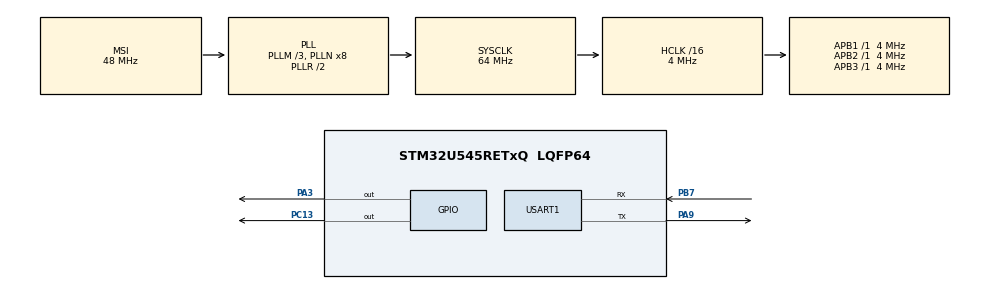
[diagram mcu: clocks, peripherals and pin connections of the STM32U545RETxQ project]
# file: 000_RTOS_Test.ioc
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CORTEX_M33_NS.userName=CORTEX_M33
Mcu.Family=STM32U5
Mcu.Name=STM32U545RETxQ
Mcu.Package=LQFP64
NVIC.PriorityGroup=NVIC_PRIORITYGROUP_4
NVIC.TIM4_IRQn=true\:15\:0\:false\:false\:true\:false\:false\:true\:true
NVIC.TimeBase=TIM4_IRQn
NVIC.TimeBaseIP=TIM4
NVIC.USART1_IRQn=true\:2\:0\:true\:false\:true\:false\:true\:true\:true
PA13\ (JTMS/SWDIO).Mode=Serial_Wire
PA13\ (JTMS/SWDIO).Signal=DEBUG_JTMS-SWDIO
PA14\ (JTCK/SWCLK).Mode=Serial_Wire
PA14\ (JTCK/SWCLK).Signal=DEBUG_JTCK-SWCLK
PA3.Signal=GPIO_Output
PA9.Mode=Asynchronous
PA9.Signal=USART1_TX
PB7.Mode=Asynchronous
PB7.Signal=USART1_RX
PC13.PinState=GPIO_PIN_SET
PC13.Signal=GPIO_Output
PWR.PowerMode=PWR_SMPS_SUPPLY
ProjectManager.HeapSize=0x200
ProjectManager.StackSize=0x400
ProjectManager.TargetToolchain=STM32CubeIDE
RCC.ADCFreq_Value=16000000
RCC.AHBCLKDivider=RCC_SYSCLK_DIV16
RCC.AHBFreq_Value=4000000
RCC.APB1Freq_Value=4000000
RCC.APB1TimFreq_Value=4000000
RCC.APB2Freq_Value=4000000
RCC.APB2TimFreq_Value=4000000
RCC.APB3Freq_Value=4000000
RCC.CortexFreq_Value=4000000
RCC.DACCLockSelectionVirtual=RCC_DAC1CLKSOURCE_LSI
RCC.DACCLockSelectionVirtualString=RCC_DAC1CLKSOURCE_LSI
RCC.EPOD_VALUE=48000000
RCC.HCLKFreq_Value=4000000
RCC.HSE_VALUE=16000000
RCC.HSI48_VALUE=48000000
RCC.HSI_VALUE=16000000
RCC.LSE_VALUE=32768
RCC.LSIDIV_VALUE=32000
RCC.MSIClockRange=RCC_MSIRANGE_0
RCC.MSI_VALUE=48000000
RCC.PLL2FRACN=0
RCC.PLL3FRACN=0
RCC.PLLFRACN=0
RCC.PLLM=3
RCC.PLLN=8
RCC.SYSCLKFreq_VALUE=64000000
RCC.SYSCLKSource=RCC_SYSCLKSOURCE_PLLCLK
RCC.USBFreq_Value=48000000
RCC.VCOOutputFreq_Value=128000000
USART1.VirtualMode-Asynchronous=VM_ASYNC
VP_ICACHE_VS_ICACHE.Mode=DirectMappedCache
VP_LPBAMQUEUE_VS_QUEUE.Mode=QUEUEMODE
VP_LPBAM_VS_SIG1.Mode=SmartRun
VP_LPBAM_VS_SIG4.Mode=LPDMA1
VP_MEMORYMAP_VS_MEMORYMAP.Mode=CurAppReg
VP_PWR_VS_LPOM.Mode=PowerOptimisation
VP_PWR_VS_SECSignals.Mode=Security/Privilege
VP_SYS_VS_tim4.Mode=TIM4
VP_THREADX_VS_RTOSJjThreadXJjCoreJjDefault.Mode=Core_Default
VP_THREADX_VS_RTOSJjThreadXJjLow_Power_Support.Mode=Low_Power_Support
VP_THREADX_VS_RTOSJjThreadXJjPerformance_InfoJjDefault.Mode=Performance_Default
VP_THREADX_VS_RTOSJjThreadXJjTraceX_SupportJjDefault.Mode=TraceX_Support_Default
board=custom

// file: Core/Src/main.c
/* USER CODE BEGIN Header */
/**
  ******************************************************************************
  * @file           : main.c
  * @brief          : Main program body
  ******************************************************************************
  * @attention
  *
  * Copyright (c) 2025 STMicroelectronics.
  * All rights reserved.
  *
  * This software is licensed under terms that can be found in the LICENSE file
  * in the root directory of this software component.
  * If no LICENSE file comes with this software, it is provided AS-IS.
  *
  ******************************************************************************
  */
/* USER CODE END Header */
#include "app_threadx.h"
#include "main.h"
#include "icache.h"
#include "memorymap.h"
#include "usart.h"
#include "gpio.h"

/* USER CODE BEGIN Includes */
#include <string.h>
#include "debug.h"
/* USER CODE END Includes */

/* USER CODE BEGIN PV */
uint8_t pData = 0;
uint8_t u1_flag = 0;

/* USER CODE END PV */

void SystemClock_Config(void);
static void SystemPower_Config(void);

/* USER CODE BEGIN 0 */
//void HAL_UART_RxCpltCallback(UART_HandleTypeDef *huart)
//{
//	if(huart == &huart1)
//	{
//		HAL_GPIO_TogglePin(GPIOC, GPIO_PIN_13);
//		u1_flag = 1;
//		HAL_UART_Receive_IT(&huart1, &pData, 1);
//	}
//}

/* USER CODE END 0 */

int main(void)
{

  /* MCU Configuration--------------------------------------------------------*/

  /* Reset of all peripherals, Initializes the Flash interface and the Systick. */
  HAL_Init();

  /* Configure the System Power */
  SystemPower_Config();

  /* Configure the system clock */
  SystemClock_Config();

  /* Initialize all configured peripherals */
  MX_GPIO_Init();
  MX_ICACHE_Init();
  MX_USART1_UART_Init();
  /* USER CODE BEGIN 2 */
  Debug_Println("System initialized!");
  Debug_Println("UART Test - Baud Rate: 115200");
  /* USER CODE END 2 */

  MX_ThreadX_Init();

  /* We should never get here as control is now taken by the scheduler */

  /* Infinite loop */
  /* USER CODE BEGIN WHILE */
  while (1)
  {
	  HAL_GPIO_TogglePin(GPIOA, GPIO_PIN_3);
	  HAL_Delay(1000);
//	  if(u1_flag == 1)
//	  {
//		  HAL_UART_Transmit(&huart1, (uint8_t*)&pData, 1, 0xffff);
//		  u1_flag = 0;
//	  }

    /* USER CODE END WHILE */

  }
}

void SystemClock_Config(void)
{
  RCC_OscInitTypeDef RCC_OscInitStruct = {0};
  RCC_ClkInitTypeDef RCC_ClkInitStruct = {0};

  /** Configure the main internal regulator output voltage
  */
  if (HAL_PWREx_ControlVoltageScaling(PWR_REGULATOR_VOLTAGE_SCALE2) != HAL_OK)
  {
    Error_Handler();
  }

  /** Initializes the CPU, AHB and APB buses clocks
  */
  RCC_OscInitStruct.OscillatorType = RCC_OSCILLATORTYPE_MSI;
  RCC_OscInitStruct.MSIState = RCC_MSI_ON;
  RCC_OscInitStruct.MSICalibrationValue = RCC_MSICALIBRATION_DEFAULT;
  RCC_OscInitStruct.MSIClockRange = RCC_MSIRANGE_0;
  RCC_OscInitStruct.PLL.PLLState = RCC_PLL_ON;
  RCC_OscInitStruct.PLL.PLLSource = RCC_PLLSOURCE_MSI;
  RCC_OscInitStruct.PLL.PLLMBOOST = RCC_PLLMBOOST_DIV4;
  RCC_OscInitStruct.PLL.PLLM = 3;
  RCC_OscInitStruct.PLL.PLLN = 8;
  RCC_OscInitStruct.PLL.PLLP = 2;
  RCC_OscInitStruct.PLL.PLLQ = 2;
  RCC_OscInitStruct.PLL.PLLR = 2;
  RCC_OscInitStruct.PLL.PLLRGE = RCC_PLLVCIRANGE_1;
  RCC_OscInitStruct.PLL.PLLFRACN = 0;
  if (HAL_RCC_OscConfig(&RCC_OscInitStruct) != HAL_OK)
  {
    Error_Handler();
  }

  /** Initializes the CPU, AHB and APB buses clocks
  */
  RCC_ClkInitStruct.ClockType = RCC_CLOCKTYPE_HCLK|RCC_CLOCKTYPE_SYSCLK
                              |RCC_CLOCKTYPE_PCLK1|RCC_CLOCKTYPE_PCLK2
                              |RCC_CLOCKTYPE_PCLK3;
  RCC_ClkInitStruct.SYSCLKSource = RCC_SYSCLKSOURCE_PLLCLK;
  RCC_ClkInitStruct.AHBCLKDivider = RCC_SYSCLK_DIV16;
  RCC_ClkInitStruct.APB1CLKDivider = RCC_HCLK_DIV1;
  RCC_ClkInitStruct.APB2CLKDivider = RCC_HCLK_DIV1;
  RCC_ClkInitStruct.APB3CLKDivider = RCC_HCLK_DIV1;

  if (HAL_RCC_ClockConfig(&RCC_ClkInitStruct, FLASH_LATENCY_0) != HAL_OK)
  {
    Error_Handler();
  }
}

/**
  * @brief Power Configuration
  * @retval None
  */
static void SystemPower_Config(void)
{

  /*
   * Switch to SMPS regulator instead of LDO
   */
  if (HAL_PWREx_ConfigSupply(PWR_SMPS_SUPPLY) != HAL_OK)
  {
    Error_Handler();
  }
}

void HAL_TIM_PeriodElapsedCallback(TIM_HandleTypeDef *htim)
{
  if (htim->Instance == TIM4) {
    HAL_IncTick();
  }
}

void Error_Handler(void)
{
  __disable_irq();
  while (1)
  {
  }
}
